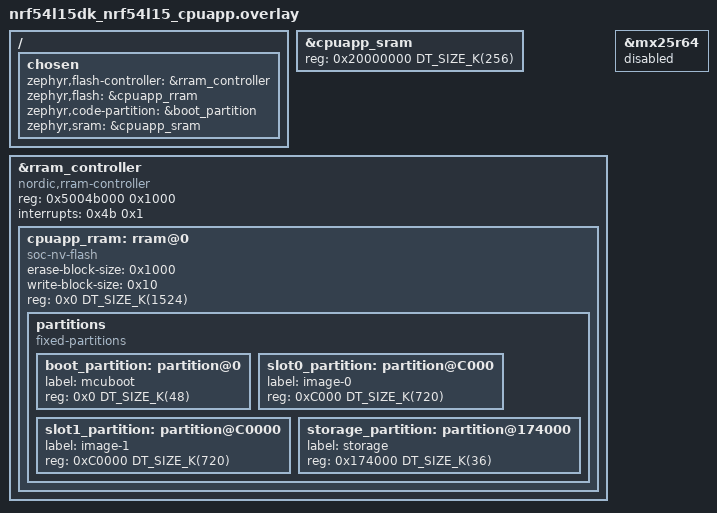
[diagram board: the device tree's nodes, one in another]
/ {
	chosen {
		zephyr,flash-controller = &rram_controller;
		zephyr,flash = &cpuapp_rram;
		zephyr,code-partition = &boot_partition;
		zephyr,sram = &cpuapp_sram;
	};
};
/* Adjust the cpuapp_sram to include the freed up cpuflpr_sram */
&cpuapp_sram {
	reg = <0x20000000 DT_SIZE_K(256)>;
	ranges = <0x0 0x20000000 0x20040000>;
};

&rram_controller {
	/delete-node/ cpuflpr_sram;
	/delete-node/ cpuflpr_rram;
	compatible = "nordic,rram-controller";
	reg = < 0x5004b000 0x1000 >;
	#address-cells = < 0x1 >;
	#size-cells = < 0x1 >;
	interrupts = < 0x4b 0x1 >;
	cpuapp_rram: rram@0 {
		compatible = "soc-nv-flash";
		erase-block-size = < 0x1000 >;
		write-block-size = < 0x10 >;
		reg = < 0x0 DT_SIZE_K(1524) >;
		/delete-node/ partitions;

		partitions {
			compatible = "fixed-partitions";
			#address-cells = < 0x1 >;
			#size-cells = < 0x1 >;
			boot_partition: partition@0 {
				label = "mcuboot";
				reg = < 0x0 DT_SIZE_K(48) >;
			};
			slot0_partition: partition@C000 {
				label = "image-0";
				reg = < 0xC000 DT_SIZE_K(720) >;
			};
			slot1_partition: partition@C0000 {
				label = "image-1";
				reg = < 0xC0000 DT_SIZE_K(720) >;
			};
			storage_partition: partition@174000 {
				label = "storage";
				reg = < 0x174000 DT_SIZE_K(36) >;
			};
		};
	};
};


&mx25r64 {
	status = "disabled";
};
